# w600 register map
File version: 1.0
Registers are 32-bit, read-write, reset 0x0 unless marked. A register's access mark holds for its fields unless they carry their own. Offsets are from the block's base; lines under a group give offsets from that group; [hi:lo] are bit positions; {n}, {i} and the like mark numbered series; 'fields as' and 'values as' point back to an identical list; <NAME> marks a mode.

## Memory map
0x40000000 CLK blocks up to offset 0x720 — Timer and Reset
0x40000000 DMA blocks up to offset 0x580 — Direct Memory Access
0x40002200 RSA size 0x40C — RSA Accelerator
0x40003200 Crypto size 0x5C — Crypto Accelerator

## CLK — Timer and Reset
Base 0x40000000
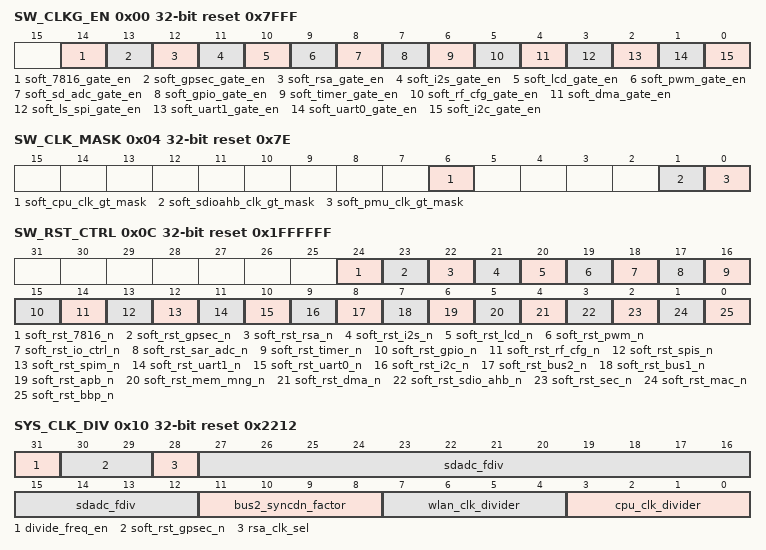
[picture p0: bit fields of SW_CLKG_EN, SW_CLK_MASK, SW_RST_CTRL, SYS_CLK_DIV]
0x00 SW_CLKG_EN reset 0x7FFF — 软件时钟门控使能寄存器
  [14] soft_7816_gate_en, [13] soft_gpsec_gate_en, [12] soft_rsa_gate_en, [11] soft_i2s_gate_en, [10] soft_lcd_gate_en, [9] soft_pwm_gate_en, [8] soft_sd_adc_gate_en, [7] soft_gpio_gate_en, [6] soft_timer_gate_en, [5] soft_rf_cfg_gate_en, [4] soft_dma_gate_en, [3] soft_ls_spi_gate_en, [2] soft_uart1_gate_en, [1] soft_uart0_gate_en, [0] soft_i2c_gate_en
0x04 SW_CLK_MASK reset 0x7E — 软件时钟掩码寄存器
  [6] soft_cpu_clk_gt_mask, [1] soft_sdioahb_clk_gt_mask, [0] soft_pmu_clk_gt_mask
0x0C SW_RST_CTRL reset 0x1FFFFFF — 软件复位控制寄存器
  [24] soft_rst_7816_n, [23] soft_rst_gpsec_n, [22] soft_rst_rsa_n, [21] soft_rst_i2s_n, [20] soft_rst_lcd_n, [19] soft_rst_pwm_n, [18] soft_rst_io_ctrl_n, [17] soft_rst_sar_adc_n, [16] soft_rst_timer_n, [15] soft_rst_gpio_n, [14] soft_rst_rf_cfg_n, [13] soft_rst_spis_n, [12] soft_rst_spim_n, [11] soft_rst_uart1_n, [10] soft_rst_uart0_n, [9] soft_rst_i2c_n, [8] soft_rst_bus2_n, [7] soft_rst_bus1_n, [6] soft_rst_apb_n, [5] soft_rst_mem_mng_n, [4] soft_rst_dma_n, [3] soft_rst_sdio_ahb_n, [2] soft_rst_sec_n, [1] soft_rst_mac_n, [0] soft_rst_bbp_n
0x10 SYS_CLK_DIV reset 0x2212 — 时钟分频配置寄存器
  [31] divide_freq_en, [30:29] soft_rst_gpsec_n, [28] rsa_clk_sel, [27:12] sdadc_fdiv, [11:8] bus2_syncdn_factor, [7:4] wlan_clk_divider, [3:0] cpu_clk_divider
0x14 DEBUG_CTRL — 调试控制寄存器
  [5] JTAG
0x18 I2S_CLK_CTRL — I2S时钟控制寄存器

## DMA — Direct Memory Access
Base 0x40000000
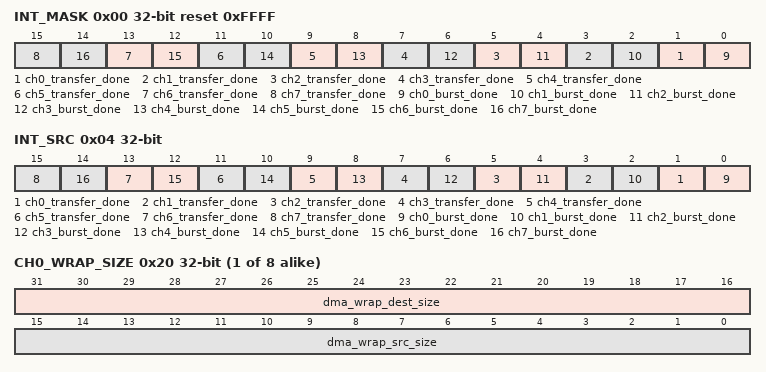
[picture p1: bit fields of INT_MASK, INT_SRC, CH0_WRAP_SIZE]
0x00 INT_MASK reset 0xFFFF — 中断屏蔽寄存器
  [2n+1] ch{n}_transfer_done (n=0..7) — channel{n} transfer_done中断屏蔽，高有效。
  [2n] ch{n}_burst_done (n=0..7) — channel{n} burst_done中断屏蔽，高有效。
0x04 INT_SRC — 中断状态寄存器
  [2n+1] ch{n}_transfer_done (n=0..7) — channel{n} transfer_done中断状态，写1清0。DMA传输完成产生中断。
  [2n] ch{n}_burst_done (n=0..7) — burst_done中断状态，写1清0。DMA burst完成产生中断。
0x08 UART_CH — UART选择寄存器
{0x10+0x30*i} CH{i}_SRC_ADDR (i=0..7) — DMA源地址寄存器
{0x14+0x30*i} CH{i}_DEST_ADDR (i=0..7) — DMA目的地址寄存器
{0x18+0x30*i} CH{i}_SRC_WRAP_ADDR (i=0..7) — DMA循环源起始地址寄存器
{0x1C+0x30*i} CH{i}_DEST_WRAP_ADDR (i=0..7) — DMA循环目的起始地址寄存器
{0x20+0x30*i} CH{i}_WRAP_SIZE (i=0..7) — DMA循环长度寄存器
  [31:16] dma_wrap_dest_size — 循环模式下，DMA目的地址循环长度。
  [15:0] dma_wrap_src_size — 循环模式下，DMA源地址循环长度。
{0x24+0x30*i} CH{i}_CHNL_CTRL (i=0..7) — DMA通道控制寄存器
{0x28+0x30*i} CH{i}_DMA_MODE (i=0..7) — DMA模式选择寄存器
{0x2C+0x30*i} CH{i}_DMA_CTRL (i=0..7) — DMA数据流控制寄存器
{0x30+0x30*i} CH{i}_DMA_STATUS (i=0..7) ro — DMA传输字节数寄存器
{0x34+0x30*i} CH{i}_DESC_ADDR (i=0..7) — DMA链表入口地址寄存器
{0x38+0x30*i} CH{i}_CUR_DEST_ADDR (i=0..7) ro — DMA当前目的地址寄存器

## Crypto — Crypto Accelerator
Base 0x40003200
0x00 SRC_ADDR — Source address register
0x04 DEST_ADDR — Destination address register
0x08 GPSEC_CFG — Configuration register
  [30] RNG_start
  [29] RNG_LOAD_SEED — RNG load seed as random
  [28] RNG_SWITCH — RNG generate bits
  [27] DES_SOFT_RESET — des soft reset 0
  [26] AES_SOFT_RESET — aes soft reset 0
  [25] RC4_SOFT_RESET — rc4 soft reset 0
  [24] CRC_DATA_REC — crc data reserve
  [23] CRC_CHK_REC — check crc reserved
  [22:21] SUB_MODE — sub mode for cryptography algorithm
  [20] ENC_DEC — encrypt or decrypt
  [19] INT_MASK — interrupt mask for enc or dec done
  [18:16] CYPHER_MODE — select cryptography algorithm
  [16:15] TOTAL_BYTES — total bytes need encrypt or decrypt.
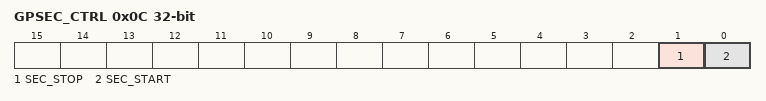
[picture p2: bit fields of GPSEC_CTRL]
0x0C GPSEC_CTRL — Control register
  [1] SEC_STOP — stop encrypt or decrypt
  [0] SEC_START — stop encrypt or decrypt.
0x10 KEY00 — Secret key 0 low register
0x14 KEY01 — Secret key 0 high register
0x18 KEY10 — Secret key 1 low register
0x1C KEY11 — Secret key 1 high register
0x20 KEY20 — Secret key 2 low register
0x24 KEY21 — Secret key 2 high register
0x28 IV00 — Initial vector low register
0x2C IV00 — Initial vector high register
0x30 GPSEC_STS — Status register
  [1] INT_DONE — interrupt mask when encrypt or decrypt done.
  [15:0] TRANSFER_CNT — total decrypt complete bytes.
0x34 DIGEST0 reset 0x67452301
0x38 DIGEST1 reset 0xEFCDAB89
0x3C DIGEST2 reset 0x98BADCFE
0x40 DIGEST3 reset 0x10325476
0x44 DIGEST4 reset 0xC3D2E1F0
0x48 RNG_RESULT — RNG output

## RSA — RSA Accelerator
Base 0x40002200
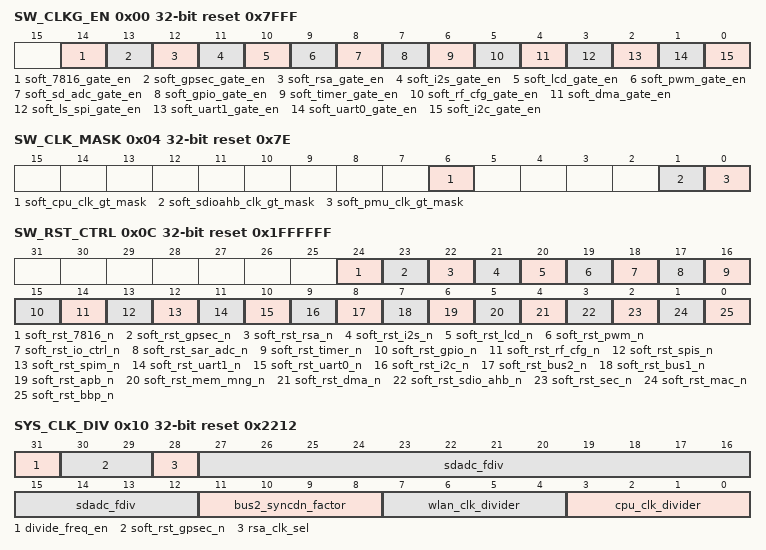
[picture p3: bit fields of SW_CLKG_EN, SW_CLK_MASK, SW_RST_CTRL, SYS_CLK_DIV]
0x00 SW_CLKG_EN reset 0x7FFF — 软件时钟门控使能寄存器
  fields as CLK.SW_CLKG_EN
0x04 SW_CLK_MASK reset 0x7E — 软件时钟掩码寄存器
  [6] soft_cpu_clk_gt_mask, [1] soft_sdioahb_clk_gt_mask, [0] soft_pmu_clk_gt_mask
0x0C SW_RST_CTRL reset 0x1FFFFFF — 软件复位控制寄存器
  fields as CLK.SW_RST_CTRL
0x10 SYS_CLK_DIV reset 0x2212 — 时钟分频配置寄存器
  [31] divide_freq_en, [30:29] soft_rst_gpsec_n, [28] rsa_clk_sel, [27:12] sdadc_fdiv, [11:8] bus2_syncdn_factor, [7:4] wlan_clk_divider, [3:0] cpu_clk_divider
0x14 DEBUG_CTRL — 调试控制寄存器
  [5] JTAG
0x18 I2S_CLK_CTRL — I2S时钟控制寄存器
